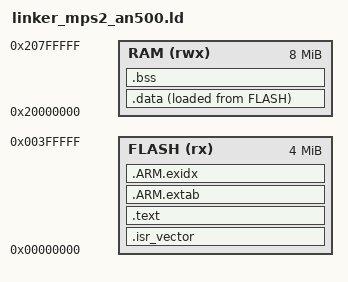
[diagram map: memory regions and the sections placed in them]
/* Linker script for MPS2-AN500 Cortex-M7 QEMU */
MEMORY
{
  FLASH (rx)  : ORIGIN = 0x00000000, LENGTH = 4M
  RAM   (rwx) : ORIGIN = 0x20000000, LENGTH = 8M
}

/* Top of stack - QEMU ignores size but reserves */
_estack = ORIGIN(RAM) + LENGTH(RAM);

ENTRY(Reset_Handler)

SECTIONS
{
  .isr_vector :
  {
    . = ALIGN(4);
    KEEP(*(.isr_vector))
    . = ALIGN(4);
  } >FLASH

  .text :
  {
    . = ALIGN(4);
    *(.text)
    *(.text*)
    *(.glue_7)
    *(.glue_7t)
    *(.eh_frame)
    KEEP (*(.init))
    KEEP (*(.fini))
    *(.rodata)
    *(.rodata*)
    . = ALIGN(4);
  } >FLASH

  .ARM.extab :
  {
    *(.ARM.extab* .gnu.linkonce.armextab.*)
  } >FLASH

  .ARM.exidx :
  {
    *(.ARM.exidx*)
  } >FLASH

  /* .data LMA in Flash, VMA in RAM */
  _sidata = LOADADDR(.data);

  .data :
  {
    . = ALIGN(4);
    _sdata = .;
    *(.data)
    *(.data*)
    . = ALIGN(4);
    _edata = .;
  } >RAM AT>FLASH

  .bss :
  {
    . = ALIGN(4);
    _sbss = .;
    *(.bss)
    *(.bss*)
    *(COMMON)
    . = ALIGN(4);
    _ebss = .;
  } >RAM

  /* for _sbrk heap */
  _end = _ebss;

  /* Remove debug info we don't need in final */
  /DISCARD/ :
  {
    *(.comment)
    *(.ARM.attributes)
  }
}
